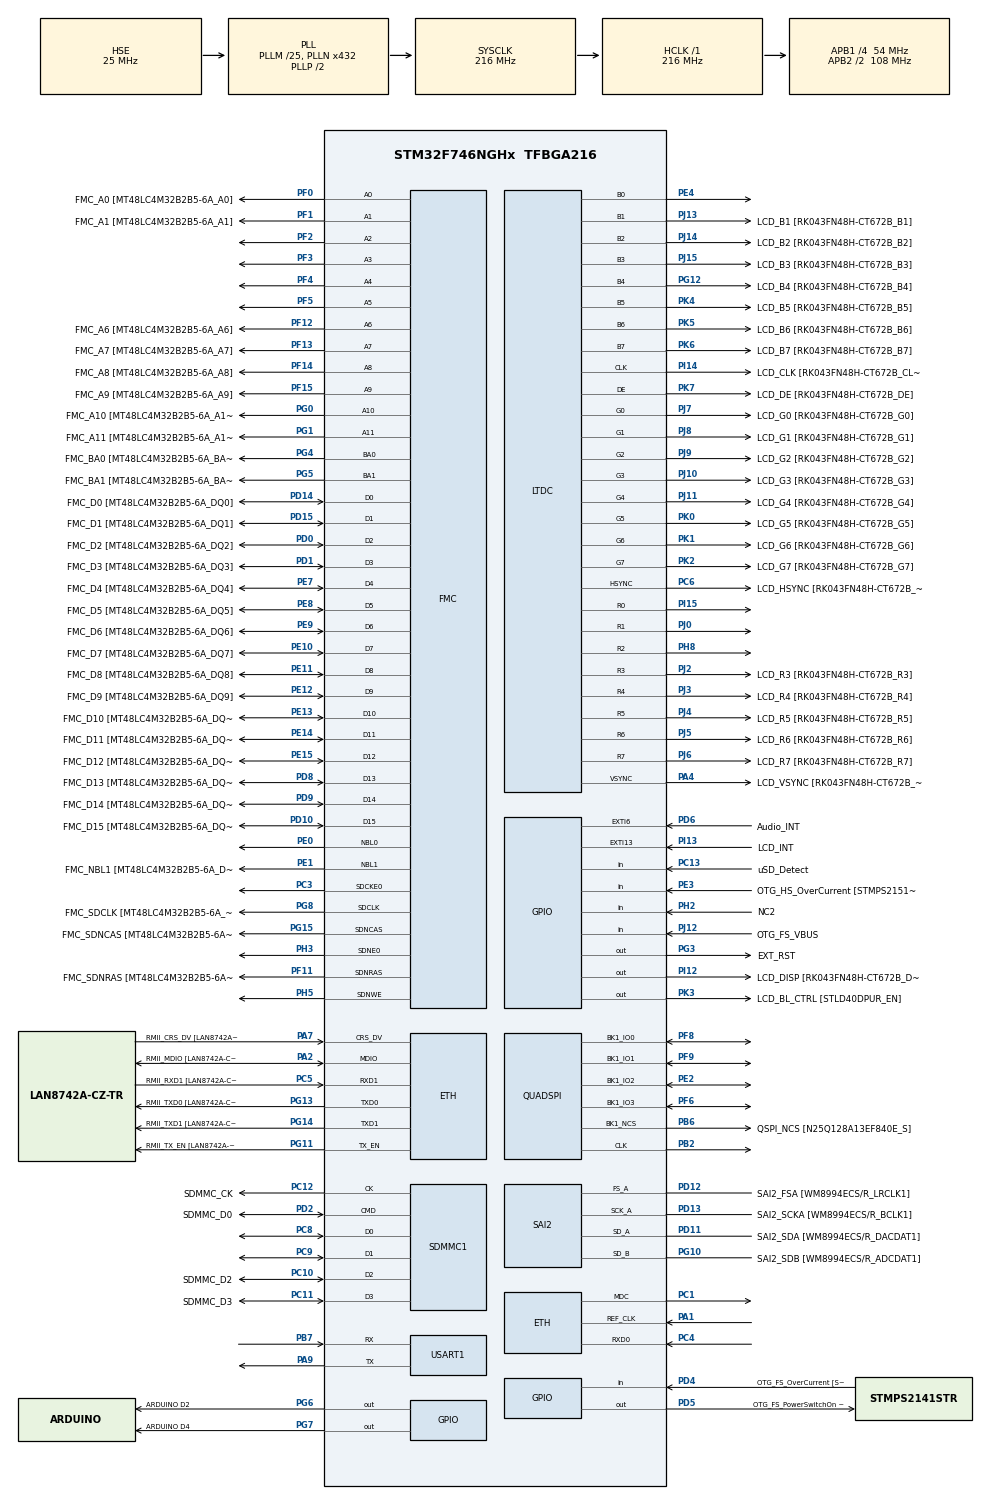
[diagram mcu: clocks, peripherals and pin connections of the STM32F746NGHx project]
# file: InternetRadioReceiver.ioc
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CORTEX_M7.ART_ACCLERATOR_ENABLE=1
CORTEX_M7.AccessPermission-Cortex_Memory_Protection_Unit_Region0_Settings=MPU_REGION_FULL_ACCESS
CORTEX_M7.AccessPermission-Cortex_Memory_Protection_Unit_Region1_Settings=MPU_REGION_FULL_ACCESS
CORTEX_M7.BaseAddress-Cortex_Memory_Protection_Unit_Region0_Settings=0x90000000
CORTEX_M7.BaseAddress-Cortex_Memory_Protection_Unit_Region1_Settings=0x90000000
CORTEX_M7.CPU_DCache=Disabled
CORTEX_M7.CPU_ICache=Enabled
CORTEX_M7.Enable-Cortex_Memory_Protection_Unit_Region0_Settings=MPU_REGION_ENABLE
CORTEX_M7.Enable-Cortex_Memory_Protection_Unit_Region1_Settings=MPU_REGION_ENABLE
CORTEX_M7.Enable-Cortex_Memory_Protection_Unit_Region2_Settings=__NULL
CORTEX_M7.IsCacheable-Cortex_Memory_Protection_Unit_Region1_Settings=MPU_ACCESS_CACHEABLE
CORTEX_M7.MPU_Control=MPU_PRIVILEGED_DEFAULT
CORTEX_M7.PREFETCH_ENABLE=1
CORTEX_M7.Size-Cortex_Memory_Protection_Unit_Region0_Settings=MPU_REGION_SIZE_256MB
CORTEX_M7.Size-Cortex_Memory_Protection_Unit_Region1_Settings=MPU_REGION_SIZE_16MB
DMA2D.ColorMode=DMA2D_OUTPUT_ARGB8888
Dma.Request0=SDMMC1_RX
Dma.Request1=SDMMC1_TX
Dma.SDMMC1_RX.0.Direction=DMA_PERIPH_TO_MEMORY
Dma.SDMMC1_RX.0.FIFOMode=DMA_FIFOMODE_ENABLE
Dma.SDMMC1_RX.0.FIFOThreshold=DMA_FIFO_THRESHOLD_FULL
Dma.SDMMC1_RX.0.Instance=DMA2_Stream3
Dma.SDMMC1_RX.0.MemBurst=DMA_MBURST_INC4
Dma.SDMMC1_RX.0.MemDataAlignment=DMA_MDATAALIGN_WORD
Dma.SDMMC1_RX.0.MemInc=DMA_MINC_ENABLE
Dma.SDMMC1_RX.0.Mode=DMA_PFCTRL
Dma.SDMMC1_RX.0.PeriphBurst=DMA_PBURST_INC4
Dma.SDMMC1_RX.0.PeriphDataAlignment=DMA_PDATAALIGN_WORD
Dma.SDMMC1_RX.0.PeriphInc=DMA_PINC_DISABLE
Dma.SDMMC1_RX.0.Priority=DMA_PRIORITY_LOW
Dma.SDMMC1_TX.1.Direction=DMA_MEMORY_TO_PERIPH
Dma.SDMMC1_TX.1.FIFOMode=DMA_FIFOMODE_ENABLE
Dma.SDMMC1_TX.1.FIFOThreshold=DMA_FIFO_THRESHOLD_FULL
Dma.SDMMC1_TX.1.Instance=DMA2_Stream6
Dma.SDMMC1_TX.1.MemBurst=DMA_MBURST_INC4
Dma.SDMMC1_TX.1.MemDataAlignment=DMA_MDATAALIGN_WORD
Dma.SDMMC1_TX.1.MemInc=DMA_MINC_ENABLE
Dma.SDMMC1_TX.1.Mode=DMA_PFCTRL
Dma.SDMMC1_TX.1.PeriphBurst=DMA_PBURST_INC4
Dma.SDMMC1_TX.1.PeriphDataAlignment=DMA_PDATAALIGN_WORD
Dma.SDMMC1_TX.1.PeriphInc=DMA_PINC_DISABLE
Dma.SDMMC1_TX.1.Priority=DMA_PRIORITY_LOW
ETH.MediaInterface=ETH_MEDIA_INTERFACE_RMII
ETH.PhyAddress=0
ETH.RxMode=ETH_RXINTERRUPT_MODE
FATFS.BSP.number=1
FATFS._FS_LOCK=4
FATFS._FS_REENTRANT=1
FATFS._FS_TIMEOUT=500
FATFS._LFN_UNICODE=0
FATFS._MAX_SS=4096
FATFS._MIN_SS=512
FATFS._STRF_ENCODE=0
FATFS._USE_LFN=3
FATFS._USE_MUTEX=1
FATFS0.BSP.STBoard=false
FATFS0.BSP.api=Unknown
FATFS0.BSP.i2caddr=0
FATFS0.BSP.instance=PC13
FATFS0.BSP.ip=GPIO
FATFS0.BSP.mode=Input
FATFS0.BSP.name=Detect_SDIO
FATFS0.BSP.solution=PC13
FMC.CASLatency1=FMC_SDRAM_CAS_LATENCY_3
FMC.ExitSelfRefreshDelay1=7
FMC.LoadToActiveDelay1=2
FMC.RCDDelay1=2
FMC.RPDelay1=2
FMC.ReadBurst1=FMC_SDRAM_RBURST_ENABLE
FMC.ReadBurst2=FMC_SDRAM_RBURST_ENABLE
FMC.RowCycleDelay1=6
FMC.SDClockPeriod1=FMC_SDRAM_CLOCK_PERIOD_2
FMC.SelfRefreshTime1=4
FMC.WriteRecoveryTime1=3
FREERTOS.Tasks01=defaultTask,24,1024,StartDefaultTask,Default,NULL,Dynamic,NULL,NULL
FREERTOS.configMAX_TASK_NAME_LEN=64
FREERTOS.configTOTAL_HEAP_SIZE=41000
FREERTOS.configUSE_NEWLIB_REENTRANT=1
LTDC.ActiveH=272
LTDC.ActiveW=480
LTDC.Alpha_L0=255
LTDC.FBStartAdress_L0=0xC0000000
LTDC.HBP=13
LTDC.HFP=32
LTDC.HSync=41
LTDC.ImageHeight_L0=272
LTDC.ImageWidth_L0=480
LTDC.Layers=0
LTDC.PixelFormat_L0=LTDC_PIXEL_FORMAT_RGB888
LTDC.VSPolarity=LTDC_VSPOLARITY_AL
LTDC.VSync=10
LTDC.WindowX1_L0=480
LTDC.WindowY1_L0=272
LWIP.DEFAULT_THREAD_STACKSIZE=1024
LWIP.LWIP_DNS=1
LWIP.LWIP_SO_RCVTIMEO=1
LWIP.LWIP_SO_SNDTIMEO=1
LWIP.MEMP_NUM_PBUF=2
LWIP.MEMP_NUM_TCP_PCB_LISTEN=4
LWIP.MEMP_NUM_TCP_SEG=9
LWIP.MEM_SIZE=1500
LWIP.PBUF_POOL_SIZE=11
LWIP.TCPIP_THREAD_STACKSIZE=1024
LWIP.TCP_MSS=512
LWIP.Version=v2.1.2_Cube
Mcu.Family=STM32F7
Mcu.Name=STM32F746NGHx
Mcu.Package=TFBGA216
NVIC.DMA2D_IRQn=true\:5\:0\:false\:false\:true\:true\:true\:true
NVIC.DMA2_Stream3_IRQn=true\:5\:0\:false\:false\:true\:true\:false\:true
NVIC.DMA2_Stream6_IRQn=true\:5\:0\:false\:false\:true\:true\:false\:true
NVIC.ETH_IRQn=true\:5\:0\:false\:false\:true\:true\:false\:true
NVIC.LTDC_ER_IRQn=true\:5\:0\:false\:false\:true\:true\:true\:true
NVIC.LTDC_IRQn=true\:5\:0\:false\:false\:true\:true\:true\:true
NVIC.PriorityGroup=NVIC_PRIORITYGROUP_4
NVIC.RCC_IRQn=true\:5\:0\:false\:false\:true\:true\:true\:false
NVIC.SDMMC1_IRQn=true\:5\:0\:false\:false\:true\:true\:true\:true
PA1.Mode=RMII
PA1.Signal=ETH_REF_CLK
PA10.GPIO_Label=OTG_FS_ID
PA10.Signal=USB_OTG_FS_ID
PA11.GPIO_Label=OTG_FS_N
PA11.Signal=USB_OTG_FS_DM
PA12.GPIO_Label=OTG_FS_P
PA12.Signal=USB_OTG_FS_DP
PA13.GPIO_Label=SWDIO
PA13.Mode=Trace_Asynchronous_SW
PA13.Signal=SYS_JTMS-SWDIO
PA14.GPIO_Label=SWCLK
PA14.Mode=Trace_Asynchronous_SW
PA14.Signal=SYS_JTCK-SWCLK
PA15.GPIO_Label=ARDUINO PWM/D9
PA15.GPIO_ModeDefaultPP=GPIO_MODE_AF_PP
PA15.GPIO_PuPd=GPIO_NOPULL
PA15.GPIO_Speed=GPIO_SPEED_FREQ_LOW
PA15.Signal=S_TIM2_CH1_ETR
PA2.GPIO_Label=RMII_MDIO [LAN8742A-CZ-TR_MDIO]
PA2.Mode=RMII
PA2.Signal=ETH_MDIO
PA4.GPIO_Label=LCD_VSYNC [RK043FN48H-CT672B_VSYNC]
PA4.Mode=RGB888
PA4.Signal=LTDC_VSYNC
PA7.GPIO_Label=RMII_CRS_DV [LAN8742A-CZ-TR_CRS_DV]
PA7.Mode=RMII
PA7.Signal=ETH_CRS_DV
PA8.GPIO_Label=ARDUINO PWM/D10
PA8.GPIO_ModeDefaultPP=GPIO_MODE_AF_PP
PA8.GPIO_PuPd=GPIO_NOPULL
PA8.GPIO_Speed=GPIO_SPEED_FREQ_LOW
PA8.Signal=S_TIM1_CH1
PA9.Mode=Asynchronous
PA9.Signal=USART1_TX
PB12.GPIO_Label=ULPI_D5 [USB3320C-EZK_D5]
PB12.Signal=USB_OTG_HS_ULPI_D5
PB13.GPIO_Label=ULPI_D6 [USB3320C-EZK_D6]
PB13.Signal=USB_OTG_HS_ULPI_D6
PB2.Mode=Single Bank 1
PB2.Signal=QUADSPI_CLK
PB3.GPIO_Label=SWO
PB3.Mode=Trace_Asynchronous_SW
PB3.Signal=SYS_JTDO-SWO
PB4.GPIO_Label=ARDUINO PWM/D3
PB4.GPIO_ModeDefaultPP=GPIO_MODE_AF_PP
PB4.GPIO_PuPd=GPIO_NOPULL
PB4.GPIO_Speed=GPIO_SPEED_FREQ_LOW
PB4.Signal=S_TIM3_CH1
PB6.GPIO_Label=QSPI_NCS [N25Q128A13EF840E_S]
PB6.Mode=Single Bank 1
PB6.Signal=QUADSPI_BK1_NCS
PB7.Mode=Asynchronous
PB7.Signal=USART1_RX
PB8.GPIO_Label=ARDUINO SCL/D15
PB8.GPIO_Mode=GPIO_MODE_AF_OD
PB8.GPIO_PuPd=GPIO_NOPULL
PB8.GPIO_Speed=GPIO_SPEED_FREQ_LOW
PB8.Signal=I2C1_SCL
PC1.Mode=RMII
PC1.Signal=ETH_MDC
PC10.GPIO_Label=SDMMC_D2
PC10.Mode=SD_4_bits_Wide_bus
PC10.Signal=SDMMC1_D2
PC11.GPIO_Label=SDMMC_D3
PC11.Mode=SD_4_bits_Wide_bus
PC11.Signal=SDMMC1_D3
PC12.GPIO_Label=SDMMC_CK
PC12.Mode=SD_4_bits_Wide_bus
PC12.Signal=SDMMC1_CK
PC13.GPIO_Label=uSD_Detect
PC13.Signal=GPIO_Input
PC14/OSC32_IN.GPIO_Label=RCC_OSC32_IN
PC14/OSC32_IN.Signal=RCC_OSC32_IN
PC15/OSC32_OUT.GPIO_Label=RCC_OSC32_OUT
PC15/OSC32_OUT.Signal=RCC_OSC32_OUT
PC3.Mode=SdramChipSelect1_1
PC3.Signal=FMC_SDCKE0
PC4.Mode=RMII
PC4.Signal=ETH_RXD0
PC5.GPIO_Label=RMII_RXD1 [LAN8742A-CZ-TR_RXD1]
PC5.Mode=RMII
PC5.Signal=ETH_RXD1
PC6.GPIO_Label=LCD_HSYNC [RK043FN48H-CT672B_HSYNC]
PC6.Mode=RGB888
PC6.Signal=LTDC_HSYNC
PC7.GPIO_Label=ARDUINO RX/D0
PC7.Signal=USART6_RX
PC8.Mode=SD_4_bits_Wide_bus
PC8.Signal=SDMMC1_D0
PC9.Mode=SD_4_bits_Wide_bus
PC9.Signal=SDMMC1_D1
PD0.GPIO_Label=FMC_D2 [MT48LC4M32B2B5-6A_DQ2]
PD0.Signal=FMC_D2_DA2
PD1.GPIO_Label=FMC_D3 [MT48LC4M32B2B5-6A_DQ3]
PD1.Signal=FMC_D3_DA3
PD10.GPIO_Label=FMC_D15 [MT48LC4M32B2B5-6A_DQ15]
PD10.Signal=FMC_D15_DA15
PD11.GPIO_Label=SAI2_SDA [WM8994ECS/R_DACDAT1]
PD11.Mode=SAI_A_Master
PD11.Signal=SAI2_SD_A
PD12.GPIO_Label=SAI2_FSA [WM8994ECS/R_LRCLK1]
PD12.Mode=SAI_A_Master
PD12.Signal=SAI2_FS_A
PD13.GPIO_Label=SAI2_SCKA [WM8994ECS/R_BCLK1]
PD13.Mode=SAI_A_Master
PD13.Signal=SAI2_SCK_A
PD14.GPIO_Label=FMC_D0 [MT48LC4M32B2B5-6A_DQ0]
PD14.Signal=FMC_D0_DA0
PD15.GPIO_Label=FMC_D1 [MT48LC4M32B2B5-6A_DQ1]
PD15.Signal=FMC_D1_DA1
PD2.GPIO_Label=SDMMC_D0
PD2.Mode=SD_4_bits_Wide_bus
PD2.Signal=SDMMC1_CMD
PD3.GPIO_Label=DCMI_D5
PD3.Signal=DCMI_D5
PD4.GPIO_Label=OTG_FS_OverCurrent [STMPS2141STR_Fault]
PD4.Signal=GPIO_Input
PD5.GPIO_Label=OTG_FS_PowerSwitchOn [STMPS2141STR_EN]
PD5.PinState=GPIO_PIN_SET
PD5.Signal=GPIO_Output
PD6.GPIO_Label=Audio_INT
PD6.GPIO_ModeDefaultEXTI=GPIO_MODE_EVT_RISING
PD6.Signal=GPXTI6
PD7.GPIO_Label=SPDIF_RX0 [74LVC1G04SE_4]
PD7.Signal=SPDIFRX_IN0
PD8.GPIO_Label=FMC_D13 [MT48LC4M32B2B5-6A_DQ13]
PD8.Signal=FMC_D13_DA13
PD9.GPIO_Label=FMC_D14 [MT48LC4M32B2B5-6A_DQ14]
PD9.Signal=FMC_D14_DA14
PE0.Signal=FMC_NBL0
PE1.GPIO_Label=FMC_NBL1 [MT48LC4M32B2B5-6A_DQM1]
PE1.Signal=FMC_NBL1
PE10.GPIO_Label=FMC_D7 [MT48LC4M32B2B5-6A_DQ7]
PE10.Signal=FMC_D7_DA7
PE11.GPIO_Label=FMC_D8 [MT48LC4M32B2B5-6A_DQ8]
PE11.Signal=FMC_D8_DA8
PE12.GPIO_Label=FMC_D9 [MT48LC4M32B2B5-6A_DQ9]
PE12.Signal=FMC_D9_DA9
PE13.GPIO_Label=FMC_D10 [MT48LC4M32B2B5-6A_DQ10]
PE13.Signal=FMC_D10_DA10
PE14.GPIO_Label=FMC_D11 [MT48LC4M32B2B5-6A_DQ11]
PE14.Signal=FMC_D11_DA11
PE15.GPIO_Label=FMC_D12 [MT48LC4M32B2B5-6A_DQ12]
PE15.Signal=FMC_D12_DA12
PE2.Mode=Single Bank 1
PE2.Signal=QUADSPI_BK1_IO2
PE3.GPIO_Label=OTG_HS_OverCurrent [STMPS2151STR_FAULT]
PE3.Signal=GPIO_Input
PE4.Mode=RGB888
PE4.Signal=LTDC_B0
PE7.GPIO_Label=FMC_D4 [MT48LC4M32B2B5-6A_DQ4]
PE7.Signal=FMC_D4_DA4
PE8.GPIO_Label=FMC_D5 [MT48LC4M32B2B5-6A_DQ5]
PE8.Signal=FMC_D5_DA5
PE9.GPIO_Label=FMC_D6 [MT48LC4M32B2B5-6A_DQ6]
PE9.Signal=FMC_D6_DA6
PF0.GPIO_Label=FMC_A0 [MT48LC4M32B2B5-6A_A0]
PF0.Signal=FMC_A0
PF1.GPIO_Label=FMC_A1 [MT48LC4M32B2B5-6A_A1]
PF1.Signal=FMC_A1
PF11.GPIO_Label=FMC_SDNRAS [MT48LC4M32B2B5-6A_RAS]
PF11.Signal=FMC_SDNRAS
PF12.GPIO_Label=FMC_A6 [MT48LC4M32B2B5-6A_A6]
PF12.Signal=FMC_A6
PF13.GPIO_Label=FMC_A7 [MT48LC4M32B2B5-6A_A7]
PF13.Signal=FMC_A7
PF14.GPIO_Label=FMC_A8 [MT48LC4M32B2B5-6A_A8]
PF14.Signal=FMC_A8
PF15.GPIO_Label=FMC_A9 [MT48LC4M32B2B5-6A_A9]
PF15.Signal=FMC_A9
PF2.Signal=FMC_A2
PF3.Signal=FMC_A3
PF4.Signal=FMC_A4
PF5.Signal=FMC_A5
PF6.Mode=Single Bank 1
PF6.Signal=QUADSPI_BK1_IO3
PF8.Mode=Single Bank 1
PF8.Signal=QUADSPI_BK1_IO0
PF9.Mode=Single Bank 1
PF9.Signal=QUADSPI_BK1_IO1
PG0.GPIO_Label=FMC_A10 [MT48LC4M32B2B5-6A_A10]
PG0.Signal=FMC_A10
PG1.GPIO_Label=FMC_A11 [MT48LC4M32B2B5-6A_A11]
PG1.Signal=FMC_A11
PG10.GPIO_Label=SAI2_SDB [WM8994ECS/R_ADCDAT1]
PG10.Mode=SAI_B_SyncSlave
PG10.Signal=SAI2_SD_B
PG11.GPIO_Label=RMII_TX_EN [LAN8742A-CZ-TR_TXEN]
PG11.Mode=RMII
PG11.Signal=ETH_TX_EN
PG12.GPIO_Label=LCD_B4 [RK043FN48H-CT672B_B4]
PG12.Mode=RGB888
PG12.Signal=LTDC_B4
PG13.GPIO_Label=RMII_TXD0 [LAN8742A-CZ-TR_TXD0]
PG13.Mode=RMII
PG13.Signal=ETH_TXD0
PG14.GPIO_Label=RMII_TXD1 [LAN8742A-CZ-TR_TXD1]
PG14.Mode=RMII
PG14.Signal=ETH_TXD1
PG15.GPIO_Label=FMC_SDNCAS [MT48LC4M32B2B5-6A_CAS]
PG15.Signal=FMC_SDNCAS
PG3.GPIO_Label=EXT_RST
PG3.Signal=GPIO_Output
PG4.GPIO_Label=FMC_BA0 [MT48LC4M32B2B5-6A_BA0]
PG4.Signal=FMC_A14_BA0
PG5.GPIO_Label=FMC_BA1 [MT48LC4M32B2B5-6A_BA1]
PG5.Signal=FMC_A15_BA1
PG6.GPIO_Label=ARDUINO D2
PG6.Signal=GPIO_Output
PG7.GPIO_Label=ARDUINO D4
PG7.Signal=GPIO_Output
PG8.GPIO_Label=FMC_SDCLK [MT48LC4M32B2B5-6A_CLK]
PG8.Signal=FMC_SDCLK
PH0/OSC_IN.GPIO_Label=OSC_25M [NZ2520SB-25.00M_OUT]
PH0/OSC_IN.Mode=HSE-External-Oscillator
PH0/OSC_IN.Signal=RCC_OSC_IN
PH1/OSC_OUT.Mode=HSE-External-Oscillator
PH1/OSC_OUT.Signal=RCC_OSC_OUT
PH2.GPIO_Label=NC2
PH2.Signal=GPIO_Input
PH3.Mode=SdramChipSelect1_1
PH3.Signal=FMC_SDNE0
PH4.GPIO_Label=ULPI_NXT [USB3320C-EZK_NXT]
PH4.Signal=USB_OTG_HS_ULPI_NXT
PH5.Signal=FMC_SDNWE
PH8.Mode=RGB888
PH8.Signal=LTDC_R2
PI12.GPIO_Label=LCD_DISP [RK043FN48H-CT672B_DISP] 
PI12.Signal=GPIO_Output
PI13.GPIO_Label=LCD_INT
PI13.GPIO_ModeDefaultEXTI=GPIO_MODE_EVT_RISING
PI13.Signal=GPXTI13
PI14.GPIO_Label=LCD_CLK [RK043FN48H-CT672B_CLK]
PI14.Mode=RGB888
PI14.Signal=LTDC_CLK
PI15.Mode=RGB888
PI15.Signal=LTDC_R0
PI8.GPIO_Label=NC1 [TP2]
PI8.Signal=RTC_TS
PJ0.Mode=RGB888
PJ0.Signal=LTDC_R1
PJ10.GPIO_Label=LCD_G3 [RK043FN48H-CT672B_G3]
PJ10.Mode=RGB888
PJ10.Signal=LTDC_G3
PJ11.GPIO_Label=LCD_G4 [RK043FN48H-CT672B_G4]
PJ11.Mode=RGB888
PJ11.Signal=LTDC_G4
PJ12.GPIO_Label=OTG_FS_VBUS
PJ12.Signal=GPIO_Input
PJ13.GPIO_Label=LCD_B1 [RK043FN48H-CT672B_B1]
PJ13.Mode=RGB888
PJ13.Signal=LTDC_B1
PJ14.GPIO_Label=LCD_B2 [RK043FN48H-CT672B_B2]
PJ14.Mode=RGB888
PJ14.Signal=LTDC_B2
PJ15.GPIO_Label=LCD_B3 [RK043FN48H-CT672B_B3]
PJ15.Mode=RGB888
PJ15.Signal=LTDC_B3
PJ2.GPIO_Label=LCD_R3 [RK043FN48H-CT672B_R3]
PJ2.Mode=RGB888
PJ2.Signal=LTDC_R3
PJ3.GPIO_Label=LCD_R4 [RK043FN48H-CT672B_R4]
PJ3.Mode=RGB888
PJ3.Signal=LTDC_R4
PJ4.GPIO_Label=LCD_R5 [RK043FN48H-CT672B_R5]
PJ4.Mode=RGB888
PJ4.Signal=LTDC_R5
PJ5.GPIO_Label=LCD_R6 [RK043FN48H-CT672B_R6]
PJ5.Mode=RGB888
PJ5.Signal=LTDC_R6
PJ6.GPIO_Label=LCD_R7 [RK043FN48H-CT672B_R7]
PJ6.Mode=RGB888
PJ6.Signal=LTDC_R7
PJ7.GPIO_Label=LCD_G0 [RK043FN48H-CT672B_G0]
PJ7.Mode=RGB888
PJ7.Signal=LTDC_G0
PJ8.GPIO_Label=LCD_G1 [RK043FN48H-CT672B_G1]
PJ8.Mode=RGB888
PJ8.Signal=LTDC_G1
PJ9.GPIO_Label=LCD_G2 [RK043FN48H-CT672B_G2]
PJ9.Mode=RGB888
PJ9.Signal=LTDC_G2
PK0.GPIO_Label=LCD_G5 [RK043FN48H-CT672B_G5]
PK0.Mode=RGB888
PK0.Signal=LTDC_G5
PK1.GPIO_Label=LCD_G6 [RK043FN48H-CT672B_G6]
PK1.Mode=RGB888
PK1.Signal=LTDC_G6
PK2.GPIO_Label=LCD_G7 [RK043FN48H-CT672B_G7]
PK2.Mode=RGB888
PK2.Signal=LTDC_G7
PK3.GPIO_Label=LCD_BL_CTRL [STLD40DPUR_EN]
PK3.Signal=GPIO_Output
PK4.GPIO_Label=LCD_B5 [RK043FN48H-CT672B_B5]
PK4.Mode=RGB888
PK4.Signal=LTDC_B5
PK5.GPIO_Label=LCD_B6 [RK043FN48H-CT672B_B6]
PK5.Mode=RGB888
PK5.Signal=LTDC_B6
PK6.GPIO_Label=LCD_B7 [RK043FN48H-CT672B_B7]
PK6.Mode=RGB888
PK6.Signal=LTDC_B7
PK7.GPIO_Label=LCD_DE [RK043FN48H-CT672B_DE]
PK7.Mode=RGB888
PK7.Signal=LTDC_DE
ProjectManager.HeapSize=0x400
ProjectManager.StackSize=0x800
ProjectManager.TargetToolchain=STM32CubeIDE
QUADSPI.ChipSelectHighTime=QSPI_CS_HIGH_TIME_6_CYCLE
QUADSPI.ClockPrescaler=1
QUADSPI.FifoThreshold=4
QUADSPI.FlashSize=24
QUADSPI.SampleShifting=QSPI_SAMPLE_SHIFTING_HALFCYCLE
RCC.AHBFreq_Value=216000000
RCC.APB1CLKDivider=RCC_HCLK_DIV4
RCC.APB1Freq_Value=54000000
RCC.APB1TimFreq_Value=108000000
RCC.APB2CLKDivider=RCC_HCLK_DIV2
RCC.APB2Freq_Value=108000000
RCC.APB2TimFreq_Value=216000000
RCC.CortexFreq_Value=216000000
RCC.HCLKFreq_Value=216000000
RCC.HSE_VALUE=25000000
RCC.HSI_VALUE=16000000
RCC.LSE_VALUE=32768
RCC.PLLM=25
RCC.PLLN=432
RCC.PLLQ=9
RCC.PLLSAIN=400
RCC.PLLSAIP=RCC_PLLSAIP_DIV4
RCC.PLLSAIQDiv=4
RCC.PLLSAIRDiv=RCC_PLLSAIDIVR_16
RCC.PLLSourceVirtual=RCC_PLLSOURCE_HSE
RCC.SDMMCClockSelection=RCC_SDMMC1CLKSOURCE_CLK48
RCC.SYSCLKFreq_VALUE=216000000
RCC.SYSCLKSource=RCC_SYSCLKSOURCE_PLLCLK
RCC.USBFreq_Value=48000000
RCC.VCOOutputFreq_Value=432000000
SAI2.ErrorAudioFreq-SAI_A_Master=1.72 %
SAI2.Instance-SAI_A_Master=SAI$Index_Block_A
SAI2.Instance-SAI_B_SyncSlave=SAI$Index_Block_B
SAI2.MClockEnable-SAI_A_Master=SAI_MASTERCLOCK_DISABLE
SAI2.RealAudioFreq-SAI_A_Master=195.312 KHz
SAI2.VirtualMode-SAI_A_Master=VM_MASTER
SAI2.VirtualMode-SAI_B_SyncSlave=VM_SLAVE
SDMMC1.ClockDiv=8
SH.FMC_A0.0=FMC_A0,12b-sda1
SH.FMC_A1.0=FMC_A1,12b-sda1
SH.FMC_A10.0=FMC_A10,12b-sda1
SH.FMC_A11.0=FMC_A11,12b-sda1
SH.FMC_A14_BA0.0=FMC_BA0,FourSdramBanks1
SH.FMC_A15_BA1.0=FMC_BA1,FourSdramBanks1
SH.FMC_A2.0=FMC_A2,12b-sda1
SH.FMC_A3.0=FMC_A3,12b-sda1
SH.FMC_A4.0=FMC_A4,12b-sda1
SH.FMC_A5.0=FMC_A5,12b-sda1
SH.FMC_A6.0=FMC_A6,12b-sda1
SH.FMC_A7.0=FMC_A7,12b-sda1
SH.FMC_A8.0=FMC_A8,12b-sda1
SH.FMC_A9.0=FMC_A9,12b-sda1
SH.FMC_D0_DA0.0=FMC_D0,sd-16b-d1
SH.FMC_D10_DA10.0=FMC_D10,sd-16b-d1
SH.FMC_D11_DA11.0=FMC_D11,sd-16b-d1
SH.FMC_D12_DA12.0=FMC_D12,sd-16b-d1
SH.FMC_D13_DA13.0=FMC_D13,sd-16b-d1
SH.FMC_D14_DA14.0=FMC_D14,sd-16b-d1
SH.FMC_D15_DA15.0=FMC_D15,sd-16b-d1
SH.FMC_D1_DA1.0=FMC_D1,sd-16b-d1
SH.FMC_D2_DA2.0=FMC_D2,sd-16b-d1
SH.FMC_D3_DA3.0=FMC_D3,sd-16b-d1
SH.FMC_D4_DA4.0=FMC_D4,sd-16b-d1
SH.FMC_D5_DA5.0=FMC_D5,sd-16b-d1
SH.FMC_D6_DA6.0=FMC_D6,sd-16b-d1
SH.FMC_D7_DA7.0=FMC_D7,sd-16b-d1
SH.FMC_D8_DA8.0=FMC_D8,sd-16b-d1
SH.FMC_D9_DA9.0=FMC_D9,sd-16b-d1
SH.FMC_NBL0.0=FMC_NBL0,Sd2ByteEnable1
SH.FMC_NBL1.0=FMC_NBL1,Sd2ByteEnable1
SH.FMC_SDCLK.0=FMC_SDCLK,12b-sda1
SH.FMC_SDNCAS.0=FMC_SDNCAS,12b-sda1
SH.FMC_SDNRAS.0=FMC_SDNRAS,12b-sda1
SH.FMC_SDNWE.0=FMC_SDNWE,12b-sda1
SH.S_TIM1_CH1.0=TIM1_CH1
SH.S_TIM2_CH1_ETR.0=TIM2_CH1
SH.S_TIM3_CH1.0=TIM3_CH1
STMicroelectronics.X-CUBE-TOUCHGFX.4.18.0.ApplicationCcGraphicsJjApplication=TouchGFXOoGenerator
STMicroelectronics.X-CUBE-TOUCHGFX.4.18.0.tgfx_address1=0xC0000000
STMicroelectronics.X-CUBE-TOUCHGFX.4.18.0.tgfx_address2=0xC005FA00
STMicroelectronics.X-CUBE-TOUCHGFX.4.18.0.tgfx_buffering_strategy=Double
STMicroelectronics.X-CUBE-TOUCHGFX.4.18.0.tgfx_display_interface=disp_ltdc
STMicroelectronics.X-CUBE-TOUCHGFX.4.18.0.tgfx_hardware_accelerator=dma_2d
STMicroelectronics.X-CUBE-TOUCHGFX.4.18.0.tgfx_location=By Address
STMicroelectronics.X-CUBE-TOUCHGFX.4.18.0.tgfx_vsync=vsync_ltdc
STMicroelectronics.X-CUBE-TOUCHGFX.4.18.0_IsPackSelfContextualization=true
USART1.VirtualMode-Asynchronous=VM_ASYNC
VP_CRC_VS_CRC.Mode=CRC_Activate
VP_DMA2D_VS_DMA2D.Mode=DMA2D_Activate
VP_FATFS_VS_SDIO.Mode=SDIO
VP_FREERTOS_VS_CMSIS_V2.Mode=CMSIS_V2
VP_LWIP_VS_Enabled.Mode=Enabled
VP_STMicroelectronics.X-CUBE-TOUCHGFX_VS_GraphicsJjApplication_4.18.0.Mode=GraphicsJjApplication
board=STM32F746G-DISCO

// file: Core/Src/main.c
/* USER CODE BEGIN Header */
/**
  ******************************************************************************
  * @file           : main.c
  * @brief          : Main program body
  ******************************************************************************
  * @attention
  *
  * <h2><center>&copy; Copyright (c) 2021 STMicroelectronics.
  * All rights reserved.</center></h2>
  *
  * This software component is licensed by ST under BSD 3-Clause license,
  * the "License"; You may not use this file except in compliance with the
  * License. You may obtain a copy of the License at:
  *                        opensource.org/licenses/BSD-3-Clause
  *
  ******************************************************************************
  */
/* USER CODE END Header */
#include "main.h"
#include "cmsis_os.h"
#include "fatfs.h"
#include "lwip.h"
#include "app_touchgfx.h"

/* USER CODE BEGIN Includes */
#include "init.hpp"
/* USER CODE END Includes */

/* USER CODE BEGIN PD */
#define REFRESH_COUNT        1835

#define SDRAM_TIMEOUT                            ((uint32_t)0xFFFF)
#define SDRAM_MODEREG_BURST_LENGTH_1             ((uint16_t)0x0000)
#define SDRAM_MODEREG_BURST_LENGTH_2             ((uint16_t)0x0001)
#define SDRAM_MODEREG_BURST_LENGTH_4             ((uint16_t)0x0002)
#define SDRAM_MODEREG_BURST_LENGTH_8             ((uint16_t)0x0004)
#define SDRAM_MODEREG_BURST_TYPE_SEQUENTIAL      ((uint16_t)0x0000)
#define SDRAM_MODEREG_BURST_TYPE_INTERLEAVED     ((uint16_t)0x0008)
#define SDRAM_MODEREG_CAS_LATENCY_2              ((uint16_t)0x0020)
#define SDRAM_MODEREG_CAS_LATENCY_3              ((uint16_t)0x0030)
#define SDRAM_MODEREG_OPERATING_MODE_STANDARD    ((uint16_t)0x0000)
#define SDRAM_MODEREG_WRITEBURST_MODE_PROGRAMMED ((uint16_t)0x0000)
#define SDRAM_MODEREG_WRITEBURST_MODE_SINGLE     ((uint16_t)0x0200)
/* USER CODE END PD */

CRC_HandleTypeDef hcrc;

DMA2D_HandleTypeDef hdma2d;

LTDC_HandleTypeDef hltdc;

QSPI_HandleTypeDef hqspi;

SAI_HandleTypeDef hsai_BlockA2;
SAI_HandleTypeDef hsai_BlockB2;

SD_HandleTypeDef hsd1;
DMA_HandleTypeDef hdma_sdmmc1_rx;
DMA_HandleTypeDef hdma_sdmmc1_tx;

UART_HandleTypeDef huart1;

SDRAM_HandleTypeDef hsdram1;

/* Definitions for defaultTask */
osThreadId_t defaultTaskHandle;
const osThreadAttr_t defaultTask_attributes = {
  .name = "defaultTask",
  .stack_size = 1024 * 4,
  .priority = (osPriority_t) osPriorityNormal,
};
/* USER CODE BEGIN PV */
static FMC_SDRAM_CommandTypeDef Command;
/* USER CODE END PV */

void SystemClock_Config(void);
static void MPU_Config(void);
static void MX_GPIO_Init(void);
static void MX_USART1_UART_Init(void);
static void MX_SDMMC1_SD_Init(void);
static void MX_CRC_Init(void);
static void MX_DMA2D_Init(void);
static void MX_LTDC_Init(void);
static void MX_FMC_Init(void);
static void MX_SAI2_Init(void);
static void MX_QUADSPI_Init(void);
static void MX_DMA_Init(void);
void StartDefaultTask(void *argument);

int main(void)
{
  /* USER CODE BEGIN 1 */
  RCC->CFGR = 0;
  /* USER CODE END 1 */

  /* MPU Configuration--------------------------------------------------------*/
  MPU_Config();

  /* Enable I-Cache---------------------------------------------------------*/
  SCB_EnableICache();

  /* MCU Configuration--------------------------------------------------------*/

  /* Reset of all peripherals, Initializes the Flash interface and the Systick. */
  HAL_Init();

  /* Configure the system clock */
  SystemClock_Config();

  /* Initialize all configured peripherals */
  MX_GPIO_Init();
  MX_USART1_UART_Init();
  MX_SDMMC1_SD_Init();
  MX_CRC_Init();
  MX_DMA2D_Init();
  MX_LTDC_Init();
  MX_FMC_Init();
  MX_SAI2_Init();
  MX_QUADSPI_Init();
  MX_DMA_Init();
  MX_FATFS_Init();
  MX_TouchGFX_Init();

  /* Init scheduler */
  osKernelInitialize();

  /* Create the thread(s) */
  /* creation of defaultTask */
  defaultTaskHandle = osThreadNew(StartDefaultTask, NULL, &defaultTask_attributes);

  /* Start scheduler */
  osKernelStart();

  /* We should never get here as control is now taken by the scheduler */
  /* Infinite loop */
    while (1) {

    }
}

void SystemClock_Config(void)
{
  RCC_OscInitTypeDef RCC_OscInitStruct = {0};
  RCC_ClkInitTypeDef RCC_ClkInitStruct = {0};
  RCC_PeriphCLKInitTypeDef PeriphClkInitStruct = {0};

  /** Configure the main internal regulator output voltage
  */
  __HAL_RCC_PWR_CLK_ENABLE();
  __HAL_PWR_VOLTAGESCALING_CONFIG(PWR_REGULATOR_VOLTAGE_SCALE1);
  /** Initializes the RCC Oscillators according to the specified parameters
  * in the RCC_OscInitTypeDef structure.
  */
  RCC_OscInitStruct.OscillatorType = RCC_OSCILLATORTYPE_HSE;
  RCC_OscInitStruct.HSEState = RCC_HSE_ON;
  RCC_OscInitStruct.PLL.PLLState = RCC_PLL_ON;
  RCC_OscInitStruct.PLL.PLLSource = RCC_PLLSOURCE_HSE;
  RCC_OscInitStruct.PLL.PLLM = 25;
  RCC_OscInitStruct.PLL.PLLN = 432;
  RCC_OscInitStruct.PLL.PLLP = RCC_PLLP_DIV2;
  RCC_OscInitStruct.PLL.PLLQ = 9;
  if (HAL_RCC_OscConfig(&RCC_OscInitStruct) != HAL_OK)
  {
    Error_Handler();
  }
  /** Activate the Over-Drive mode
  */
  if (HAL_PWREx_EnableOverDrive() != HAL_OK)
  {
    Error_Handler();
  }
  /** Initializes the CPU, AHB and APB buses clocks
  */
  RCC_ClkInitStruct.ClockType = RCC_CLOCKTYPE_HCLK|RCC_CLOCKTYPE_SYSCLK
                              |RCC_CLOCKTYPE_PCLK1|RCC_CLOCKTYPE_PCLK2;
  RCC_ClkInitStruct.SYSCLKSource = RCC_SYSCLKSOURCE_PLLCLK;
  RCC_ClkInitStruct.AHBCLKDivider = RCC_SYSCLK_DIV1;
  RCC_ClkInitStruct.APB1CLKDivider = RCC_HCLK_DIV4;
  RCC_ClkInitStruct.APB2CLKDivider = RCC_HCLK_DIV2;

  if (HAL_RCC_ClockConfig(&RCC_ClkInitStruct, FLASH_LATENCY_7) != HAL_OK)
  {
    Error_Handler();
  }
  PeriphClkInitStruct.PeriphClockSelection = RCC_PERIPHCLK_LTDC|RCC_PERIPHCLK_USART1
                              |RCC_PERIPHCLK_SAI2|RCC_PERIPHCLK_SDMMC1
                              |RCC_PERIPHCLK_CLK48;
  PeriphClkInitStruct.PLLSAI.PLLSAIN = 400;
  PeriphClkInitStruct.PLLSAI.PLLSAIR = 2;
  PeriphClkInitStruct.PLLSAI.PLLSAIQ = 2;
  PeriphClkInitStruct.PLLSAI.PLLSAIP = RCC_PLLSAIP_DIV4;
  PeriphClkInitStruct.PLLSAIDivQ = 4;
  PeriphClkInitStruct.PLLSAIDivR = RCC_PLLSAIDIVR_16;
  PeriphClkInitStruct.Sai2ClockSelection = RCC_SAI2CLKSOURCE_PLLSAI;
  PeriphClkInitStruct.Usart1ClockSelection = RCC_USART1CLKSOURCE_PCLK2;
  PeriphClkInitStruct.Clk48ClockSelection = RCC_CLK48SOURCE_PLL;
  PeriphClkInitStruct.Sdmmc1ClockSelection = RCC_SDMMC1CLKSOURCE_CLK48;
  if (HAL_RCCEx_PeriphCLKConfig(&PeriphClkInitStruct) != HAL_OK)
  {
    Error_Handler();
  }
}

static void MX_CRC_Init(void)
{

  hcrc.Instance = CRC;
  hcrc.Init.DefaultPolynomialUse = DEFAULT_POLYNOMIAL_ENABLE;
  hcrc.Init.DefaultInitValueUse = DEFAULT_INIT_VALUE_ENABLE;
  hcrc.Init.InputDataInversionMode = CRC_INPUTDATA_INVERSION_NONE;
  hcrc.Init.OutputDataInversionMode = CRC_OUTPUTDATA_INVERSION_DISABLE;
  hcrc.InputDataFormat = CRC_INPUTDATA_FORMAT_BYTES;
  if (HAL_CRC_Init(&hcrc) != HAL_OK)
  {
    Error_Handler();
  }

}

static void MX_DMA2D_Init(void)
{

  hdma2d.Instance = DMA2D;
  hdma2d.Init.Mode = DMA2D_M2M;
  hdma2d.Init.ColorMode = DMA2D_OUTPUT_ARGB8888;
  hdma2d.Init.OutputOffset = 0;
  hdma2d.LayerCfg[1].InputOffset = 0;
  hdma2d.LayerCfg[1].InputColorMode = DMA2D_INPUT_ARGB8888;
  hdma2d.LayerCfg[1].AlphaMode = DMA2D_NO_MODIF_ALPHA;
  hdma2d.LayerCfg[1].InputAlpha = 0;
  if (HAL_DMA2D_Init(&hdma2d) != HAL_OK)
  {
    Error_Handler();
  }
  if (HAL_DMA2D_ConfigLayer(&hdma2d, 1) != HAL_OK)
  {
    Error_Handler();
  }

}

static void MX_LTDC_Init(void)
{

  LTDC_LayerCfgTypeDef pLayerCfg = {0};

  hltdc.Instance = LTDC;
  hltdc.Init.HSPolarity = LTDC_HSPOLARITY_AL;
  hltdc.Init.VSPolarity = LTDC_VSPOLARITY_AL;
  hltdc.Init.DEPolarity = LTDC_DEPOLARITY_AL;
  hltdc.Init.PCPolarity = LTDC_PCPOLARITY_IPC;
  hltdc.Init.HorizontalSync = 40;
  hltdc.Init.VerticalSync = 9;
  hltdc.Init.AccumulatedHBP = 53;
  hltdc.Init.AccumulatedVBP = 11;
  hltdc.Init.AccumulatedActiveW = 533;
  hltdc.Init.AccumulatedActiveH = 283;
  hltdc.Init.TotalWidth = 565;
  hltdc.Init.TotalHeigh = 285;
  hltdc.Init.Backcolor.Blue = 0;
  hltdc.Init.Backcolor.Green = 0;
  hltdc.Init.Backcolor.Red = 0;
  if (HAL_LTDC_Init(&hltdc) != HAL_OK)
  {
    Error_Handler();
  }
  pLayerCfg.WindowX0 = 0;
  pLayerCfg.WindowX1 = 480;
  pLayerCfg.WindowY0 = 0;
  pLayerCfg.WindowY1 = 272;
  pLayerCfg.PixelFormat = LTDC_PIXEL_FORMAT_RGB888;
  pLayerCfg.Alpha = 255;
  pLayerCfg.Alpha0 = 0;
  pLayerCfg.BlendingFactor1 = LTDC_BLENDING_FACTOR1_CA;
  pLayerCfg.BlendingFactor2 = LTDC_BLENDING_FACTOR2_CA;
  pLayerCfg.FBStartAdress = 0xC0000000;
  pLayerCfg.ImageWidth = 480;
  pLayerCfg.ImageHeight = 272;
  pLayerCfg.Backcolor.Blue = 0;
  pLayerCfg.Backcolor.Green = 0;
  pLayerCfg.Backcolor.Red = 0;
  if (HAL_LTDC_ConfigLayer(&hltdc, &pLayerCfg, 0) != HAL_OK)
  {
    Error_Handler();
  }

}

static void MX_QUADSPI_Init(void)
{

  /* QUADSPI parameter configuration*/
  hqspi.Instance = QUADSPI;
  hqspi.Init.ClockPrescaler = 1;
  hqspi.Init.FifoThreshold = 4;
  hqspi.Init.SampleShifting = QSPI_SAMPLE_SHIFTING_HALFCYCLE;
  hqspi.Init.FlashSize = 24;
  hqspi.Init.ChipSelectHighTime = QSPI_CS_HIGH_TIME_6_CYCLE;
  hqspi.Init.ClockMode = QSPI_CLOCK_MODE_0;
  hqspi.Init.FlashID = QSPI_FLASH_ID_1;
  hqspi.Init.DualFlash = QSPI_DUALFLASH_DISABLE;
  if (HAL_QSPI_Init(&hqspi) != HAL_OK)
  {
    Error_Handler();
  }

}

static void MX_SAI2_Init(void)
{

  hsai_BlockA2.Instance = SAI2_Block_A;
  hsai_BlockA2.Init.Protocol = SAI_FREE_PROTOCOL;
  hsai_BlockA2.Init.AudioMode = SAI_MODEMASTER_TX;
  hsai_BlockA2.Init.DataSize = SAI_DATASIZE_8;
  hsai_BlockA2.Init.FirstBit = SAI_FIRSTBIT_MSB;
  hsai_BlockA2.Init.ClockStrobing = SAI_CLOCKSTROBING_FALLINGEDGE;
  hsai_BlockA2.Init.Synchro = SAI_ASYNCHRONOUS;
  hsai_BlockA2.Init.OutputDrive = SAI_OUTPUTDRIVE_DISABLE;
  hsai_BlockA2.Init.NoDivider = SAI_MASTERDIVIDER_ENABLE;
  hsai_BlockA2.Init.FIFOThreshold = SAI_FIFOTHRESHOLD_EMPTY;
  hsai_BlockA2.Init.AudioFrequency = SAI_AUDIO_FREQUENCY_192K;
  hsai_BlockA2.Init.SynchroExt = SAI_SYNCEXT_DISABLE;
  hsai_BlockA2.Init.MonoStereoMode = SAI_STEREOMODE;
  hsai_BlockA2.Init.CompandingMode = SAI_NOCOMPANDING;
  hsai_BlockA2.Init.TriState = SAI_OUTPUT_NOTRELEASED;
  hsai_BlockA2.FrameInit.FrameLength = 8;
  hsai_BlockA2.FrameInit.ActiveFrameLength = 1;
  hsai_BlockA2.FrameInit.FSDefinition = SAI_FS_STARTFRAME;
  hsai_BlockA2.FrameInit.FSPolarity = SAI_FS_ACTIVE_LOW;
  hsai_BlockA2.FrameInit.FSOffset = SAI_FS_FIRSTBIT;
  hsai_BlockA2.SlotInit.FirstBitOffset = 0;
  hsai_BlockA2.SlotInit.SlotSize = SAI_SLOTSIZE_DATASIZE;
  hsai_BlockA2.SlotInit.SlotNumber = 1;
  hsai_BlockA2.SlotInit.SlotActive = 0x00000000;
  if (HAL_SAI_Init(&hsai_BlockA2) != HAL_OK)
  {
    Error_Handler();
  }
  hsai_BlockB2.Instance = SAI2_Block_B;
  hsai_BlockB2.Init.Protocol = SAI_FREE_PROTOCOL;
  hsai_BlockB2.Init.AudioMode = SAI_MODESLAVE_RX;
  hsai_BlockB2.Init.DataSize = SAI_DATASIZE_8;
  hsai_BlockB2.Init.FirstBit = SAI_FIRSTBIT_MSB;
  hsai_BlockB2.Init.ClockStrobing = SAI_CLOCKSTROBING_FALLINGEDGE;
  hsai_BlockB2.Init.Synchro = SAI_SYNCHRONOUS;
  hsai_BlockB2.Init.OutputDrive = SAI_OUTPUTDRIVE_DISABLE;
  hsai_BlockB2.Init.FIFOThreshold = SAI_FIFOTHRESHOLD_EMPTY;
  hsai_BlockB2.Init.SynchroExt = SAI_SYNCEXT_DISABLE;
  hsai_BlockB2.Init.MonoStereoMode = SAI_STEREOMODE;
  hsai_BlockB2.Init.CompandingMode = SAI_NOCOMPANDING;
  hsai_BlockB2.Init.TriState = SAI_OUTPUT_NOTRELEASED;
  hsai_BlockB2.FrameInit.FrameLength = 8;
  hsai_BlockB2.FrameInit.ActiveFrameLength = 1;
  hsai_BlockB2.FrameInit.FSDefinition = SAI_FS_STARTFRAME;
  hsai_BlockB2.FrameInit.FSPolarity = SAI_FS_ACTIVE_LOW;
  hsai_BlockB2.FrameInit.FSOffset = SAI_FS_FIRSTBIT;
  hsai_BlockB2.SlotInit.FirstBitOffset = 0;
  hsai_BlockB2.SlotInit.SlotSize = SAI_SLOTSIZE_DATASIZE;
  hsai_BlockB2.SlotInit.SlotNumber = 1;
  hsai_BlockB2.SlotInit.SlotActive = 0x00000000;
  if (HAL_SAI_Init(&hsai_BlockB2) != HAL_OK)
  {
    Error_Handler();
  }

}

static void MX_SDMMC1_SD_Init(void)
{

  hsd1.Instance = SDMMC1;
  hsd1.Init.ClockEdge = SDMMC_CLOCK_EDGE_RISING;
  hsd1.Init.ClockBypass = SDMMC_CLOCK_BYPASS_DISABLE;
  hsd1.Init.ClockPowerSave = SDMMC_CLOCK_POWER_SAVE_DISABLE;
  hsd1.Init.BusWide = SDMMC_BUS_WIDE_1B;
  hsd1.Init.HardwareFlowControl = SDMMC_HARDWARE_FLOW_CONTROL_DISABLE;
  hsd1.Init.ClockDiv = 8;

}

static void MX_USART1_UART_Init(void)
{

  huart1.Instance = USART1;
  huart1.Init.BaudRate = 115200;
  huart1.Init.WordLength = UART_WORDLENGTH_8B;
  huart1.Init.StopBits = UART_STOPBITS_1;
  huart1.Init.Parity = UART_PARITY_NONE;
  huart1.Init.Mode = UART_MODE_TX_RX;
  huart1.Init.HwFlowCtl = UART_HWCONTROL_NONE;
  huart1.Init.OverSampling = UART_OVERSAMPLING_16;
  huart1.Init.OneBitSampling = UART_ONE_BIT_SAMPLE_DISABLE;
  huart1.AdvancedInit.AdvFeatureInit = UART_ADVFEATURE_NO_INIT;
  if (HAL_UART_Init(&huart1) != HAL_OK)
  {
    Error_Handler();
  }

}

static void MX_DMA_Init(void)
{

  /* DMA controller clock enable */
  __HAL_RCC_DMA2_CLK_ENABLE();

  /* DMA interrupt init */
  /* DMA2_Stream3_IRQn interrupt configuration */
  HAL_NVIC_SetPriority(DMA2_Stream3_IRQn, 5, 0);
  HAL_NVIC_EnableIRQ(DMA2_Stream3_IRQn);
  /* DMA2_Stream6_IRQn interrupt configuration */
  HAL_NVIC_SetPriority(DMA2_Stream6_IRQn, 5, 0);
  HAL_NVIC_EnableIRQ(DMA2_Stream6_IRQn);

}

/* FMC initialization function */
static void MX_FMC_Init(void)
{

  FMC_SDRAM_TimingTypeDef SdramTiming = {0};

  /** Perform the SDRAM1 memory initialization sequence
  */
  hsdram1.Instance = FMC_SDRAM_DEVICE;
  /* hsdram1.Init */
  hsdram1.Init.SDBank = FMC_SDRAM_BANK1;
  hsdram1.Init.ColumnBitsNumber = FMC_SDRAM_COLUMN_BITS_NUM_8;
  hsdram1.Init.RowBitsNumber = FMC_SDRAM_ROW_BITS_NUM_12;
  hsdram1.Init.MemoryDataWidth = FMC_SDRAM_MEM_BUS_WIDTH_16;
  hsdram1.Init.InternalBankNumber = FMC_SDRAM_INTERN_BANKS_NUM_4;
  hsdram1.Init.CASLatency = FMC_SDRAM_CAS_LATENCY_3;
  hsdram1.Init.WriteProtection = FMC_SDRAM_WRITE_PROTECTION_DISABLE;
  hsdram1.Init.SDClockPeriod = FMC_SDRAM_CLOCK_PERIOD_2;
  hsdram1.Init.ReadBurst = FMC_SDRAM_RBURST_ENABLE;
  hsdram1.Init.ReadPipeDelay = FMC_SDRAM_RPIPE_DELAY_0;
  /* SdramTiming */
  SdramTiming.LoadToActiveDelay = 2;
  SdramTiming.ExitSelfRefreshDelay = 7;
  SdramTiming.SelfRefreshTime = 4;
  SdramTiming.RowCycleDelay = 6;
  SdramTiming.WriteRecoveryTime = 3;
  SdramTiming.RPDelay = 2;
  SdramTiming.RCDDelay = 2;

  if (HAL_SDRAM_Init(&hsdram1, &SdramTiming) != HAL_OK)
  {
    Error_Handler( );
  }

  /* USER CODE BEGIN FMC_Init 2 */
    __IO uint32_t tmpmrd = 0;

    /* Step 1: Configure a clock configuration enable command */
    Command.CommandMode            = FMC_SDRAM_CMD_CLK_ENABLE;
    Command.CommandTarget          =  FMC_SDRAM_CMD_TARGET_BANK1;
    Command.AutoRefreshNumber      = 1;
    Command.ModeRegisterDefinition = 0;

    /* Send the command */
    HAL_SDRAM_SendCommand(&hsdram1, &Command, SDRAM_TIMEOUT);

    /* Step 2: Insert 100 us minimum delay */
    /* Inserted delay is equal to 1 ms due to systick time base unit (ms) */
    HAL_Delay(1);

    /* Step 3: Configure a PALL (precharge all) command */
    Command.CommandMode            = FMC_SDRAM_CMD_PALL;
    Command.CommandTarget          = FMC_SDRAM_CMD_TARGET_BANK1;
    Command.AutoRefreshNumber      = 1;
    Command.ModeRegisterDefinition = 0;

    /* Send the command */
    HAL_SDRAM_SendCommand(&hsdram1, &Command, SDRAM_TIMEOUT);

    /* Step 4: Configure an Auto Refresh command */
    Command.CommandMode            = FMC_SDRAM_CMD_AUTOREFRESH_MODE;
    Command.CommandTarget          = FMC_SDRAM_CMD_TARGET_BANK1;
    Command.AutoRefreshNumber      = 8;
    Command.ModeRegisterDefinition = 0;

    /* Send the command */
    HAL_SDRAM_SendCommand(&hsdram1, &Command, SDRAM_TIMEOUT);

    /* Step 5: Program the external memory mode register */
    tmpmrd = (uint32_t)SDRAM_MODEREG_BURST_LENGTH_1 | \
             SDRAM_MODEREG_BURST_TYPE_SEQUENTIAL    | \
             SDRAM_MODEREG_CAS_LATENCY_3            | \
             SDRAM_MODEREG_OPERATING_MODE_STANDARD  | \
             SDRAM_MODEREG_WRITEBURST_MODE_SINGLE;

    Command.CommandMode            = FMC_SDRAM_CMD_LOAD_MODE;
    Command.CommandTarget          = FMC_SDRAM_CMD_TARGET_BANK1;
    Command.AutoRefreshNumber      = 1;
    Command.ModeRegisterDefinition = tmpmrd;

    /* Send the command */
    HAL_SDRAM_SendCommand(&hsdram1, &Command, SDRAM_TIMEOUT);

    /* Step 6: Set the refresh rate counter */
    /* Set the device refresh rate */
    HAL_SDRAM_ProgramRefreshRate(&hsdram1, REFRESH_COUNT);

    //Deactivate speculative/cache access to first FMC Bank to save FMC bandwidth
    FMC_Bank1->BTCR[0] = 0x000030D2;
  /* USER CODE END FMC_Init 2 */
}

static void MX_GPIO_Init(void)
{
  GPIO_InitTypeDef GPIO_InitStruct = {0};

  /* GPIO Ports Clock Enable */
  __HAL_RCC_GPIOE_CLK_ENABLE();
  __HAL_RCC_GPIOG_CLK_ENABLE();
  __HAL_RCC_GPIOB_CLK_ENABLE();
  __HAL_RCC_GPIOD_CLK_ENABLE();
  __HAL_RCC_GPIOC_CLK_ENABLE();
  __HAL_RCC_GPIOA_CLK_ENABLE();
  __HAL_RCC_GPIOJ_CLK_ENABLE();
  __HAL_RCC_GPIOI_CLK_ENABLE();
  __HAL_RCC_GPIOK_CLK_ENABLE();
  __HAL_RCC_GPIOF_CLK_ENABLE();
  __HAL_RCC_GPIOH_CLK_ENABLE();

  /*Configure GPIO pin Output Level */
  HAL_GPIO_WritePin(OTG_FS_PowerSwitchOn_GPIO_Port, OTG_FS_PowerSwitchOn_Pin, GPIO_PIN_SET);

  /*Configure GPIO pin Output Level */
  HAL_GPIO_WritePin(LCD_BL_CTRL_GPIO_Port, LCD_BL_CTRL_Pin, GPIO_PIN_RESET);

  /*Configure GPIO pin Output Level */
  HAL_GPIO_WritePin(LCD_DISP_GPIO_Port, LCD_DISP_Pin, GPIO_PIN_RESET);

  /*Configure GPIO pin Output Level */
  HAL_GPIO_WritePin(GPIOG, ARDUINO_D4_Pin|ARDUINO_D2_Pin|EXT_RST_Pin, GPIO_PIN_RESET);

  /*Configure GPIO pin : OTG_HS_OverCurrent_Pin */
  GPIO_InitStruct.Pin = OTG_HS_OverCurrent_Pin;
  GPIO_InitStruct.Mode = GPIO_MODE_INPUT;
  GPIO_InitStruct.Pull = GPIO_NOPULL;
  HAL_GPIO_Init(OTG_HS_OverCurrent_GPIO_Port, &GPIO_InitStruct);

  /*Configure GPIO pin : ARDUINO_SCL_D15_Pin */
  GPIO_InitStruct.Pin = ARDUINO_SCL_D15_Pin;
  GPIO_InitStruct.Mode = GPIO_MODE_AF_OD;
  GPIO_InitStruct.Pull = GPIO_NOPULL;
  GPIO_InitStruct.Speed = GPIO_SPEED_FREQ_LOW;
  GPIO_InitStruct.Alternate = GPIO_AF4_I2C1;
  HAL_GPIO_Init(ARDUINO_SCL_D15_GPIO_Port, &GPIO_InitStruct);

  /*Configure GPIO pin : ARDUINO_PWM_D3_Pin */
  GPIO_InitStruct.Pin = ARDUINO_PWM_D3_Pin;
  GPIO_InitStruct.Mode = GPIO_MODE_AF_PP;
  GPIO_InitStruct.Pull = GPIO_NOPULL;
  GPIO_InitStruct.Speed = GPIO_SPEED_FREQ_LOW;
  GPIO_InitStruct.Alternate = GPIO_AF2_TIM3;
  HAL_GPIO_Init(ARDUINO_PWM_D3_GPIO_Port, &GPIO_InitStruct);

  /*Configure GPIO pin : SPDIF_RX0_Pin */
  GPIO_InitStruct.Pin = SPDIF_RX0_Pin;
  GPIO_InitStruct.Mode = GPIO_MODE_AF_PP;
  GPIO_InitStruct.Pull = GPIO_NOPULL;
  GPIO_InitStruct.Speed = GPIO_SPEED_FREQ_LOW;
  GPIO_InitStruct.Alternate = GPIO_AF8_SPDIFRX;
  HAL_GPIO_Init(SPDIF_RX0_GPIO_Port, &GPIO_InitStruct);

  /*Configure GPIO pin : ARDUINO_PWM_D9_Pin */
  GPIO_InitStruct.Pin = ARDUINO_PWM_D9_Pin;
  GPIO_InitStruct.Mode = GPIO_MODE_AF_PP;
  GPIO_InitStruct.Pull = GPIO_NOPULL;
  GPIO_InitStruct.Speed = GPIO_SPEED_FREQ_LOW;
  GPIO_InitStruct.Alternate = GPIO_AF1_TIM2;
  HAL_GPIO_Init(ARDUINO_PWM_D9_GPIO_Port, &GPIO_InitStruct);

  /*Configure GPIO pin : OTG_FS_VBUS_Pin */
  GPIO_InitStruct.Pin = OTG_FS_VBUS_Pin;
  GPIO_InitStruct.Mode = GPIO_MODE_INPUT;
  GPIO_InitStruct.Pull = GPIO_NOPULL;
  HAL_GPIO_Init(OTG_FS_VBUS_GPIO_Port, &GPIO_InitStruct);

  /*Configure GPIO pin : Audio_INT_Pin */
  GPIO_InitStruct.Pin = Audio_INT_Pin;
  GPIO_InitStruct.Mode = GPIO_MODE_EVT_RISING;
  GPIO_InitStruct.Pull = GPIO_NOPULL;
  HAL_GPIO_Init(Audio_INT_GPIO_Port, &GPIO_InitStruct);

  /*Configure GPIO pins : OTG_FS_P_Pin OTG_FS_N_Pin OTG_FS_ID_Pin */
  GPIO_InitStruct.Pin = OTG_FS_P_Pin|OTG_FS_N_Pin|OTG_FS_ID_Pin;
  GPIO_InitStruct.Mode = GPIO_MODE_AF_PP;
  GPIO_InitStruct.Pull = GPIO_NOPULL;
  GPIO_InitStruct.Speed = GPIO_SPEED_FREQ_VERY_HIGH;
  GPIO_InitStruct.Alternate = GPIO_AF10_OTG_FS;
  HAL_GPIO_Init(GPIOA, &GPIO_InitStruct);

  /*Configure GPIO pin : OTG_FS_PowerSwitchOn_Pin */
  GPIO_InitStruct.Pin = OTG_FS_PowerSwitchOn_Pin;
  GPIO_InitStruct.Mode = GPIO_MODE_OUTPUT_PP;
  GPIO_InitStruct.Pull = GPIO_NOPULL;
  GPIO_InitStruct.Speed = GPIO_SPEED_FREQ_LOW;
  HAL_GPIO_Init(OTG_FS_PowerSwitchOn_GPIO_Port, &GPIO_InitStruct);

  /*Configure GPIO pin : DCMI_D5_Pin */
  GPIO_InitStruct.Pin = DCMI_D5_Pin;
  GPIO_InitStruct.Mode = GPIO_MODE_AF_PP;
  GPIO_InitStruct.Pull = GPIO_NOPULL;
  GPIO_InitStruct.Speed = GPIO_SPEED_FREQ_LOW;
  GPIO_InitStruct.Alternate = GPIO_AF13_DCMI;
  HAL_GPIO_Init(DCMI_D5_GPIO_Port, &GPIO_InitStruct);

  /*Configure GPIO pin : uSD_Detect_Pin */
  GPIO_InitStruct.Pin = uSD_Detect_Pin;
  GPIO_InitStruct.Mode = GPIO_MODE_INPUT;
  GPIO_InitStruct.Pull = GPIO_NOPULL;
  HAL_GPIO_Init(uSD_Detect_GPIO_Port, &GPIO_InitStruct);

  /*Configure GPIO pin : LCD_BL_CTRL_Pin */
  GPIO_InitStruct.Pin = LCD_BL_CTRL_Pin;
  GPIO_InitStruct.Mode = GPIO_MODE_OUTPUT_PP;
  GPIO_InitStruct.Pull = GPIO_NOPULL;
  GPIO_InitStruct.Speed = GPIO_SPEED_FREQ_LOW;
  HAL_GPIO_Init(LCD_BL_CTRL_GPIO_Port, &GPIO_InitStruct);

  /*Configure GPIO pin : OTG_FS_OverCurrent_Pin */
  GPIO_InitStruct.Pin = OTG_FS_OverCurrent_Pin;
  GPIO_InitStruct.Mode = GPIO_MODE_INPUT;
  GPIO_InitStruct.Pull = GPIO_NOPULL;
  HAL_GPIO_Init(OTG_FS_OverCurrent_GPIO_Port, &GPIO_InitStruct);

  /*Configure GPIO pin : LCD_DISP_Pin */
  GPIO_InitStruct.Pin = LCD_DISP_Pin;
  GPIO_InitStruct.Mode = GPIO_MODE_OUTPUT_PP;
  GPIO_InitStruct.Pull = GPIO_NOPULL;
  GPIO_InitStruct.Speed = GPIO_SPEED_FREQ_LOW;
  HAL_GPIO_Init(LCD_DISP_GPIO_Port, &GPIO_InitStruct);

  /*Configure GPIO pin : ARDUINO_PWM_D10_Pin */
  GPIO_InitStruct.Pin = ARDUINO_PWM_D10_Pin;
  GPIO_InitStruct.Mode = GPIO_MODE_AF_PP;
  GPIO_InitStruct.Pull = GPIO_NOPULL;
  GPIO_InitStruct.Speed = GPIO_SPEED_FREQ_LOW;
  GPIO_InitStruct.Alternate = GPIO_AF1_TIM1;
  HAL_GPIO_Init(ARDUINO_PWM_D10_GPIO_Port, &GPIO_InitStruct);

  /*Configure GPIO pin : LCD_INT_Pin */
  GPIO_InitStruct.Pin = LCD_INT_Pin;
  GPIO_InitStruct.Mode = GPIO_MODE_EVT_RISING;
  GPIO_InitStruct.Pull = GPIO_NOPULL;
  HAL_GPIO_Init(LCD_INT_GPIO_Port, &GPIO_InitStruct);

  /*Configure GPIO pin : ARDUINO_RX_D0_Pin */
  GPIO_InitStruct.Pin = ARDUINO_RX_D0_Pin;
  GPIO_InitStruct.Mode = GPIO_MODE_AF_PP;
  GPIO_InitStruct.Pull = GPIO_NOPULL;
  GPIO_InitStruct.Speed = GPIO_SPEED_FREQ_VERY_HIGH;
  GPIO_InitStruct.Alternate = GPIO_AF8_USART6;
  HAL_GPIO_Init(ARDUINO_RX_D0_GPIO_Port, &GPIO_InitStruct);

  /*Configure GPIO pin : ULPI_NXT_Pin */
  GPIO_InitStruct.Pin = ULPI_NXT_Pin;
  GPIO_InitStruct.Mode = GPIO_MODE_AF_PP;
  GPIO_InitStruct.Pull = GPIO_NOPULL;
  GPIO_InitStruct.Speed = GPIO_SPEED_FREQ_VERY_HIGH;
  GPIO_InitStruct.Alternate = GPIO_AF10_OTG_HS;
  HAL_GPIO_Init(ULPI_NXT_GPIO_Port, &GPIO_InitStruct);

  /*Configure GPIO pins : ARDUINO_D4_Pin ARDUINO_D2_Pin EXT_RST_Pin */
  GPIO_InitStruct.Pin = ARDUINO_D4_Pin|ARDUINO_D2_Pin|EXT_RST_Pin;
  GPIO_InitStruct.Mode = GPIO_MODE_OUTPUT_PP;
  GPIO_InitStruct.Pull = GPIO_NOPULL;
  GPIO_InitStruct.Speed = GPIO_SPEED_FREQ_LOW;
  HAL_GPIO_Init(GPIOG, &GPIO_InitStruct);

  /*Configure GPIO pin : NC2_Pin */
  GPIO_InitStruct.Pin = NC2_Pin;
  GPIO_InitStruct.Mode = GPIO_MODE_INPUT;
  GPIO_InitStruct.Pull = GPIO_NOPULL;
  HAL_GPIO_Init(NC2_GPIO_Port, &GPIO_InitStruct);

  /*Configure GPIO pins : ULPI_D6_Pin ULPI_D5_Pin */
  GPIO_InitStruct.Pin = ULPI_D6_Pin|ULPI_D5_Pin;
  GPIO_InitStruct.Mode = GPIO_MODE_AF_PP;
  GPIO_InitStruct.Pull = GPIO_NOPULL;
  GPIO_InitStruct.Speed = GPIO_SPEED_FREQ_VERY_HIGH;
  GPIO_InitStruct.Alternate = GPIO_AF10_OTG_HS;
  HAL_GPIO_Init(GPIOB, &GPIO_InitStruct);

}

/* USER CODE BEGIN Header_StartDefaultTask */
/**
  * @brief  Function implementing the defaultTask thread.
  * @param  argument: Not used
  * @retval None
  */
__attribute__((noreturn))
/* USER CODE END Header_StartDefaultTask */
void StartDefaultTask(void *argument)
{
  /* init code for LWIP */
  MX_LWIP_Init();
  /* USER CODE BEGIN 5 */
  init();
  osThreadExit();
  /* USER CODE END 5 */
}

/* MPU Configuration */

void MPU_Config(void)
{
  MPU_Region_InitTypeDef MPU_InitStruct = {0};

  /* Disables the MPU */
  HAL_MPU_Disable();
  /** Initializes and configures the Region and the memory to be protected
  */
  MPU_InitStruct.Enable = MPU_REGION_ENABLE;
  MPU_InitStruct.Number = MPU_REGION_NUMBER0;
  MPU_InitStruct.BaseAddress = 0x90000000;
  MPU_InitStruct.Size = MPU_REGION_SIZE_256MB;
  MPU_InitStruct.SubRegionDisable = 0x0;
  MPU_InitStruct.TypeExtField = MPU_TEX_LEVEL0;
  MPU_InitStruct.AccessPermission = MPU_REGION_FULL_ACCESS;
  MPU_InitStruct.DisableExec = MPU_INSTRUCTION_ACCESS_ENABLE;
  MPU_InitStruct.IsShareable = MPU_ACCESS_NOT_SHAREABLE;
  MPU_InitStruct.IsCacheable = MPU_ACCESS_NOT_CACHEABLE;
  MPU_InitStruct.IsBufferable = MPU_ACCESS_NOT_BUFFERABLE;

  HAL_MPU_ConfigRegion(&MPU_InitStruct);
  /** Initializes and configures the Region and the memory to be protected
  */
  MPU_InitStruct.Number = MPU_REGION_NUMBER1;
  MPU_InitStruct.Size = MPU_REGION_SIZE_16MB;
  MPU_InitStruct.IsCacheable = MPU_ACCESS_CACHEABLE;

  HAL_MPU_ConfigRegion(&MPU_InitStruct);
  /* Enables the MPU */
  HAL_MPU_Enable(MPU_PRIVILEGED_DEFAULT);

}

void Error_Handler(void)
{
    __disable_irq();
    while (1) {
    }
}

/************************ (C) COPYRIGHT STMicroelectronics *****END OF FILE****/
